# XHSC_HC32F175 register map
Vendor: XHSC Co.Ltd; Series: ARMCM0P; File version: 1.0
CPU: CM0P r0p0, little endian, no MPU, no FPU, 3 interrupt priority bits
Registers are 32-bit, read-write, reset 0x0 unless marked. A register's access mark holds for its fields unless they carry their own. Offsets are from the block's base; [hi:lo] are bit positions; {n}, {i} and the like mark numbered series; 'fields as' and 'values as' point back to an identical list.

## SRAM
Base 0x40024C00
0x04 ERRADDR ro
  [15:0] ERRADDR
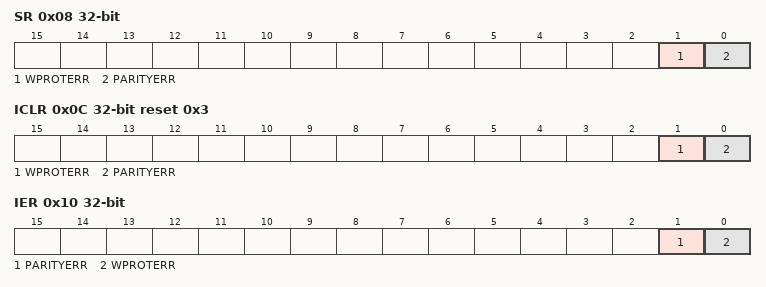
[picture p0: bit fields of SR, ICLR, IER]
0x08 SR ro
  [1] WPROTERR, [0] PARITYERR
0x0C ICLR wo reset 0x3
  [1] WPROTERR, [0] PARITYERR
0x10 IER
  [1] PARITYERR, [0] WPROTERR
0x14 LOCK wo
  [15:0] KEY
0x18 WPROT
  [5:0] WPROTSIZE

## SYSCTRL
Base 0x40025000
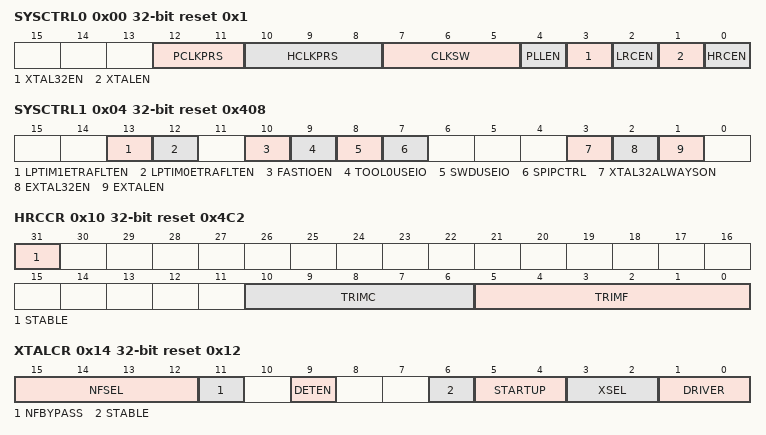
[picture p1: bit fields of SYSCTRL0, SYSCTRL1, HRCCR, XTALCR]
0x00 SYSCTRL0 reset 0x1
  [12:11] PCLKPRS, [10:8] HCLKPRS, [7:5] CLKSW, [4] PLLEN, [3] XTAL32EN, [2] LRCEN, [1] XTALEN, [0] HRCEN
0x04 SYSCTRL1 reset 0x408
  [13] LPTIM1ETRAFLTEN, [12] LPTIM0ETRAFLTEN, [10] FASTIOEN, [9] TOOL0USEIO, [8] SWDUSEIO, [7] SPIPCTRL, [3] XTAL32ALWAYSON, [2] EXTAL32EN, [1] EXTALEN
0x08 SYSCTRL2
  [15:0] SYSCTRL2 wo
0x10 HRCCR reset 0x4C2 (reset mask 0x7FF)
  [31] STABLE ro, [10:6] TRIMC, [5:0] TRIMF
0x14 XTALCR reset 0x12 (reset mask 0xFA3F)
  [15:12] NFSEL, [11] NFBYPASS, [9] DETEN, [6] STABLE ro, [5:4] STARTUP, [3:2] XSEL, [1:0] DRIVER
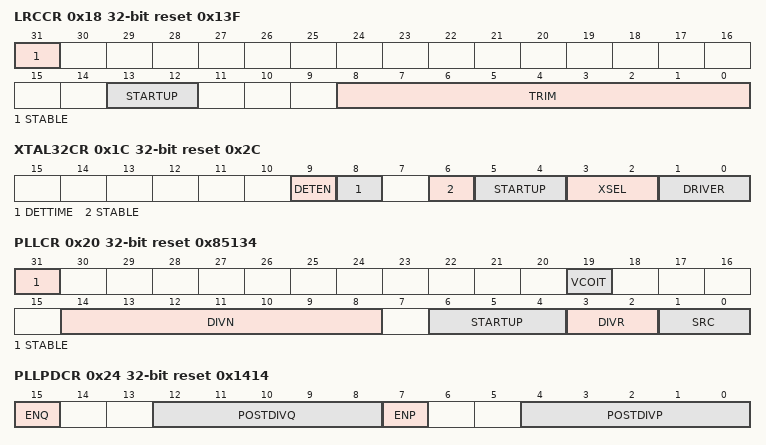
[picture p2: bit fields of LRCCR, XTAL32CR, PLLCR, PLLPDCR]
0x18 LRCCR reset 0x13F (reset mask 0x31FF)
  [31] STABLE ro, [13:12] STARTUP, [8:0] TRIM
0x1C XTAL32CR reset 0x2C (reset mask 0x33F)
  [9] DETEN, [8] DETTIME, [6] STABLE ro, [5:4] STARTUP, [3:2] XSEL, [1:0] DRIVER
0x20 PLLCR reset 0x85134 (reset mask 0xF7F7F)
  [31] STABLE ro, [19] VCOIT, [14:8] DIVN, [6:4] STARTUP, [3:2] DIVR, [1:0] SRC
0x24 PLLPDCR reset 0x1414
  [15] ENQ, [12:8] POSTDIVQ, [7] ENP, [4:0] POSTDIVP
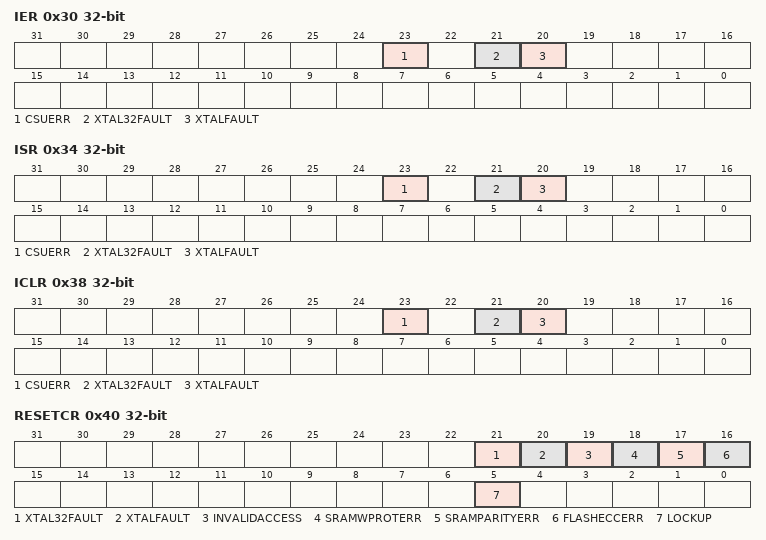
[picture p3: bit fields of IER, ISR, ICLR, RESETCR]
0x30 IER
  [23] CSUERR, [21] XTAL32FAULT, [20] XTALFAULT
0x34 ISR ro reset not defined
  [23] CSUERR, [21] XTAL32FAULT, [20] XTALFAULT
0x38 ICLR wo
  [23] CSUERR, [21] XTAL32FAULT, [20] XTALFAULT
0x40 RESETCR
  [21] XTAL32FAULT, [20] XTALFAULT, [19] INVALIDACCESS, [18] SRAMWPROTERR, [17] SRAMPARITYERR, [16] FLASHECCERR, [5] LOCKUP
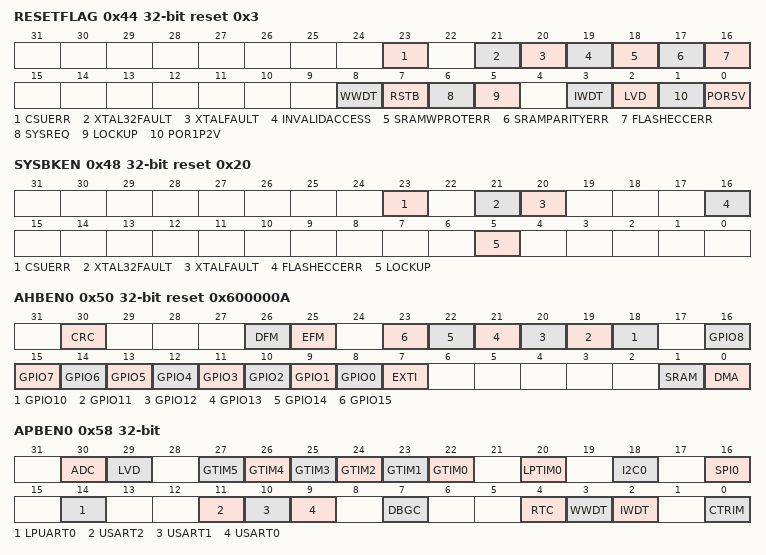
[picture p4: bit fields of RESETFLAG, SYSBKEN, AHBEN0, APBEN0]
0x44 RESETFLAG reset 0x3
  [23] CSUERR, [21] XTAL32FAULT, [20] XTALFAULT, [19] INVALIDACCESS, [18] SRAMWPROTERR, [17] SRAMPARITYERR, [16] FLASHECCERR, [8] WWDT, [7] RSTB, [6] SYSREQ, [5] LOCKUP, [3] IWDT, [2] LVD, [1] POR1P2V, [0] POR5V
0x48 SYSBKEN reset 0x20
  [23] CSUERR, [21] XTAL32FAULT, [20] XTALFAULT, [16] FLASHECCERR, [5] LOCKUP
0x50 AHBEN0 reset 0x600000A
  [30] CRC, [26] DFM, [25] EFM, [n+8] GPIO{n} (n=10..15), [n+8] GPIO{n} (n=0..8), [7] EXTI, [1] SRAM, [0] DMA
0x58 APBEN0
  [30] ADC, [29] LVD, [n+22] GTIM{n} (n=0..5), [20] LPTIM0, [18] I2C0, [16] SPI0, [14] LPUART0, [11] USART2, [10] USART1, [9] USART0, [7] DBGC, [4] RTC, [3] WWDT, [2] IWDT, [0] CTRIM
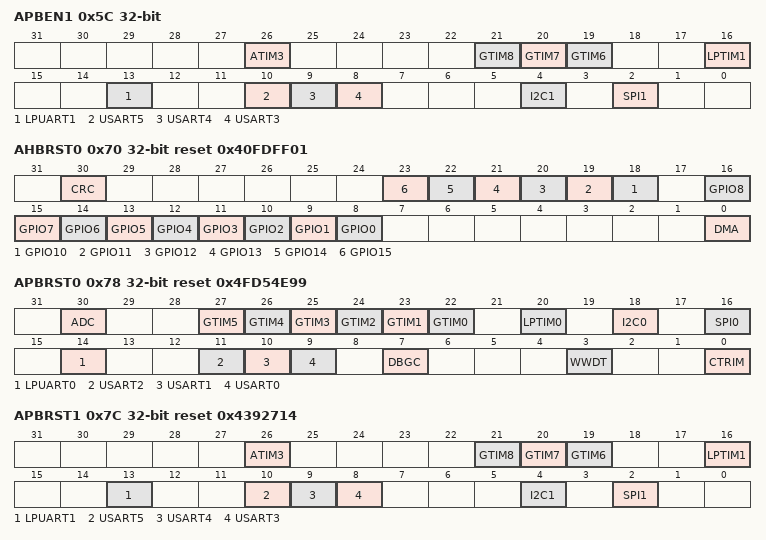
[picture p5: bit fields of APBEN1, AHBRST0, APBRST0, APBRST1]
0x5C APBEN1
  [26] ATIM3, [21] GTIM8, [20] GTIM7, [19] GTIM6, [16] LPTIM1, [13] LPUART1, [10] USART5, [9] USART4, [8] USART3, [4] I2C1, [2] SPI1
0x70 AHBRST0 reset 0x40FDFF01
  [30] CRC, [n+8] GPIO{n} (n=10..15), [n+8] GPIO{n} (n=0..8), [0] DMA
0x78 APBRST0 reset 0x4FD54E99
  [30] ADC, [n+22] GTIM{n} (n=0..5), [20] LPTIM0, [18] I2C0, [16] SPI0, [14] LPUART0, [11] USART2, [10] USART1, [9] USART0, [7] DBGC, [3] WWDT, [0] CTRIM
0x7C APBRST1 reset 0x4392714
  fields as APBEN1
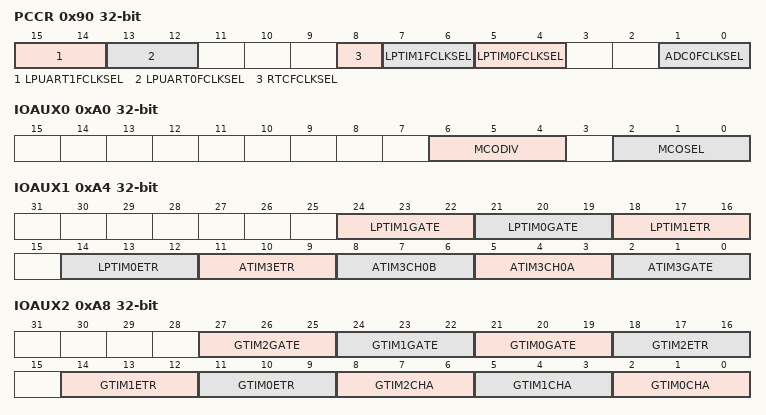
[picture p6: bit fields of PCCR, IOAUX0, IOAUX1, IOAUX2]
0x90 PCCR
  [15:14] LPUART1FCLKSEL, [13:12] LPUART0FCLKSEL, [8] RTCFCLKSEL, [7:6] LPTIM1FCLKSEL, [5:4] LPTIM0FCLKSEL, [1:0] ADC0FCLKSEL
0xA0 IOAUX0
  [6:4] MCODIV, [2:0] MCOSEL
0xA4 IOAUX1
  [24:22] LPTIM1GATE, [21:19] LPTIM0GATE, [18:16] LPTIM1ETR, [14:12] LPTIM0ETR, [11:9] ATIM3ETR, [8:6] ATIM3CH0B, [5:3] ATIM3CH0A, [2:0] ATIM3GATE
0xA8 IOAUX2
  [27:25] GTIM2GATE, [24:22] GTIM1GATE, [21:19] GTIM0GATE, [18:16] GTIM2ETR, [14:12] GTIM1ETR, [11:9] GTIM0ETR, [8:6] GTIM2CHA, [5:3] GTIM1CHA, [2:0] GTIM0CHA

## USART0 — desc USART
Base 0x40002400
Same registers: USART1 0x40002800, USART2 0x40002C00, USART3 0x4000A000, USART4 0x4000A400, USART5 0x4000A800
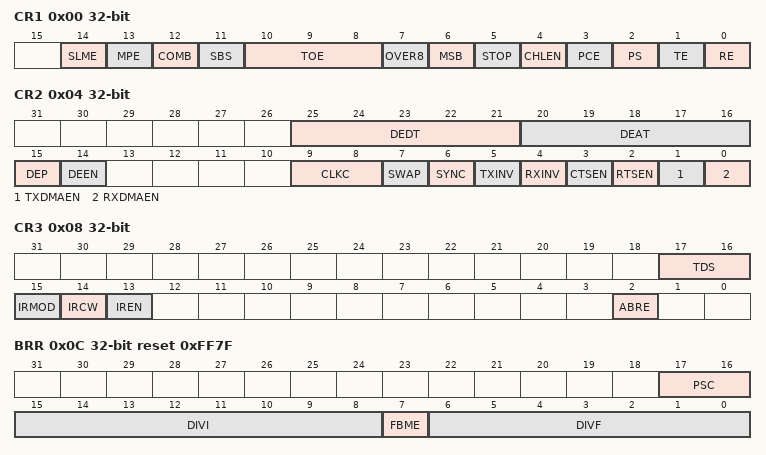
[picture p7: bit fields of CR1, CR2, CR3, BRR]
0x00 CR1
  [14] SLME, [13] MPE, [12] COMB, [11] SBS, [10:8] TOE, [7] OVER8, [6] MSB, [5] STOP, [4] CHLEN, [3] PCE, [2] PS, [1] TE, [0] RE
0x04 CR2
  [25:21] DEDT, [20:16] DEAT, [15] DEP, [14] DEEN, [9:8] CLKC, [7] SWAP, [6] SYNC, [5] TXINV, [4] RXINV, [3] CTSEN, [2] RTSEN, [1] TXDMAEN, [0] RXDMAEN
0x08 CR3
  [17:16] TDS, [15] IRMOD, [14] IRCW, [13] IREN, [2] ABRE
0x0C BRR reset 0xFF7F
  [17:16] PSC, [15:8] DIVI, [7] FBME, [6:0] DIVF
0x10 TOR
  [15:0] TOR
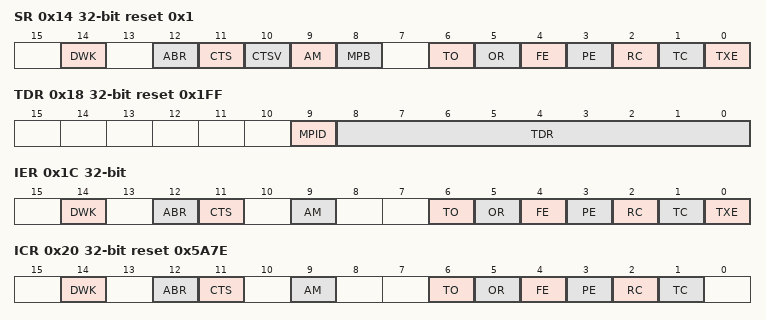
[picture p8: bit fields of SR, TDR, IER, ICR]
0x14 SR ro reset 0x1
  [14] DWK, [12] ABR, [11] CTS, [10] CTSV, [9] AM, [8] MPB, [6] TO, [5] OR, [4] FE, [3] PE, [2] RC, [1] TC, [0] TXE
0x18 TDR reset 0x1FF
  [9] MPID, [8:0] TDR
0x1C IER
  [14] DWK, [12] ABR, [11] CTS, [9] AM, [6] TO, [5] OR, [4] FE, [3] PE, [2] RC, [1] TC, [0] TXE
0x20 ICR wo reset 0x5A7E
  [14] DWK, [12] ABR, [11] CTS, [9] AM, [6] TO, [5] OR, [4] FE, [3] PE, [2] RC, [1] TC
0x24 RDR ro
  [8:0] RDR
0x28 ADDR
  [7:0] ADDR
0x2C ADDMR
  [7:0] ADDM
0x30 BDR ro
  [11:0] BDR
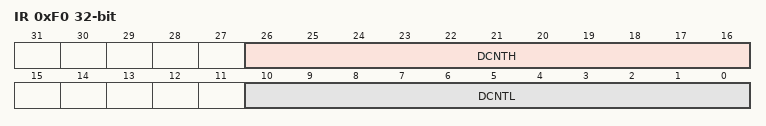
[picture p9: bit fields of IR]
0xF0 IR
  [26:16] DCNTH, [10:0] DCNTL

## WWDT
Base 0x40000C00
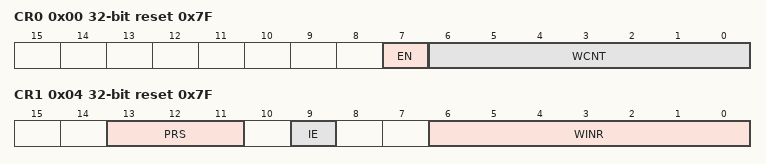
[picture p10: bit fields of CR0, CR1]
0x00 CR0 reset 0x7F
  [7] EN, [6:0] WCNT
0x04 CR1 reset 0x7F
  [13:11] PRS, [9] IE, [6:0] WINR
0x08 SR
  [0] POV
